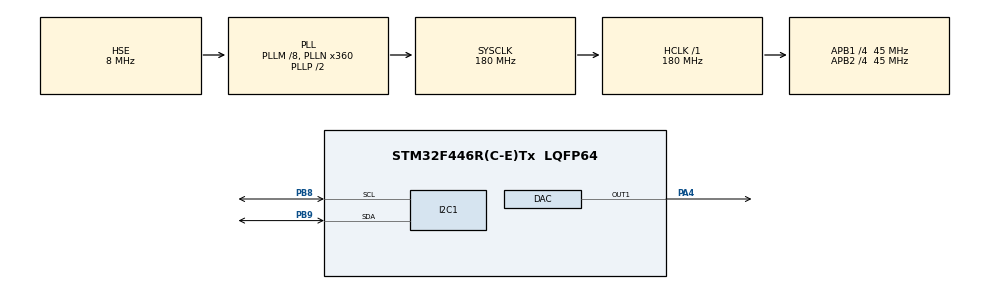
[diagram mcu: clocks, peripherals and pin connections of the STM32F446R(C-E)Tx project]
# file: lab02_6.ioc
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DAC.DAC_Trigger=DAC_TRIGGER_T6_TRGO
DAC.WaveGeneration=DISABLE
Dma.DAC1.0.Direction=DMA_MEMORY_TO_PERIPH
Dma.DAC1.0.FIFOMode=DMA_FIFOMODE_DISABLE
Dma.DAC1.0.Instance=DMA1_Stream5
Dma.DAC1.0.MemDataAlignment=DMA_MDATAALIGN_WORD
Dma.DAC1.0.MemInc=DMA_MINC_ENABLE
Dma.DAC1.0.Mode=DMA_CIRCULAR
Dma.DAC1.0.PeriphDataAlignment=DMA_PDATAALIGN_WORD
Dma.DAC1.0.PeriphInc=DMA_PINC_DISABLE
Dma.DAC1.0.Priority=DMA_PRIORITY_HIGH
Dma.Request0=DAC1
I2C1.I2C_Mode=I2C_Fast
Mcu.Family=STM32F4
Mcu.Name=STM32F446R(C-E)Tx
Mcu.Package=LQFP64
NVIC.DMA1_Stream5_IRQn=true\:0\:0\:false\:false\:true\:false\:true\:true
NVIC.PriorityGroup=NVIC_PRIORITYGROUP_4
PA13.Mode=Serial_Wire
PA13.Signal=SYS_JTMS-SWDIO
PA14.Mode=Serial_Wire
PA14.Signal=SYS_JTCK-SWCLK
PA4.Signal=COMP_DAC1_group
PB8.Mode=I2C
PB8.Signal=I2C1_SCL
PB9.Mode=I2C
PB9.Signal=I2C1_SDA
PH0-OSC_IN.Mode=HSE-External-Oscillator
PH0-OSC_IN.Signal=RCC_OSC_IN
PH1-OSC_OUT.Mode=HSE-External-Oscillator
PH1-OSC_OUT.Signal=RCC_OSC_OUT
ProjectManager.HeapSize=0x200
ProjectManager.StackSize=0x400
ProjectManager.TargetToolchain=STM32CubeIDE
RCC.AHBFreq_Value=180000000
RCC.APB1CLKDivider=RCC_HCLK_DIV4
RCC.APB1Freq_Value=45000000
RCC.APB1TimFreq_Value=90000000
RCC.APB2CLKDivider=RCC_HCLK_DIV4
RCC.APB2Freq_Value=45000000
RCC.APB2TimFreq_Value=90000000
RCC.CortexFreq_Value=180000000
RCC.HCLKFreq_Value=180000000
RCC.HSE_VALUE=8000000
RCC.PLLM=8
RCC.PLLN=360
RCC.PLLSourceVirtual=RCC_PLLSOURCE_HSE
RCC.SYSCLKFreq_VALUE=180000000
RCC.SYSCLKSource=RCC_SYSCLKSOURCE_PLLCLK
RCC.USBFreq_Value=180000000
RCC.VCOOutputFreq_Value=360000000
SH.COMP_DAC1_group.0=DAC_OUT1,DAC_OUT1
TIM6.AutoReloadPreload=TIM_AUTORELOAD_PRELOAD_ENABLE
TIM6.Period=90-1
TIM6.Prescaler=1-1
TIM6.TIM_MasterOutputTrigger=TIM_TRGO_UPDATE
VP_TIM6_VS_ClockSourceINT.Mode=Enable_Timer
board=custom

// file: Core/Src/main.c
/* USER CODE BEGIN Header */
/**
  ******************************************************************************
  * @file           : main.c
  * @brief          : Main program body
  ******************************************************************************
  * @attention
  *
  * Copyright (c) 2026 STMicroelectronics.
  * All rights reserved.
  *
  * This software is licensed under terms that can be found in the LICENSE file
  * in the root directory of this software component.
  * If no LICENSE file comes with this software, it is provided AS-IS.
  *
  ******************************************************************************
  */
/* USER CODE END Header */
#include "main.h"

/* USER CODE BEGIN Includes */
#include <math.h>
/* USER CODE END Includes */

/* USER CODE BEGIN PD */
#define PI 3.1415926536
/* USER CODE END PD */

DAC_HandleTypeDef hdac;
DMA_HandleTypeDef hdma_dac1;

I2C_HandleTypeDef hi2c1;

TIM_HandleTypeDef htim6;

/* USER CODE BEGIN PV */
uint32_t waveTable[1000];
/* USER CODE END PV */

void SystemClock_Config(void);
static void MX_GPIO_Init(void);
static void MX_DMA_Init(void);
static void MX_I2C1_Init(void);
static void MX_DAC_Init(void);
static void MX_TIM6_Init(void);

int main(void)
{

  /* USER CODE BEGIN 1 */
  int i;
  /* USER CODE END 1 */

  /* MCU Configuration--------------------------------------------------------*/

  /* Reset of all peripherals, Initializes the Flash interface and the Systick. */
  HAL_Init();

  /* Configure the system clock */
  SystemClock_Config();

  /* Initialize all configured peripherals */
  MX_GPIO_Init();
  MX_DMA_Init();
  MX_I2C1_Init();
  MX_DAC_Init();
  MX_TIM6_Init();
  /* USER CODE BEGIN 2 */
  // Generate sine wave
    for(i=0;i<1000;i++)
       waveTable[i] = (uint32_t)(sin((float)i*2*PI/1000.0)*(1241.212121)+2048);
    HAL_DAC_Start_DMA(&hdac,DAC_CHANNEL_1,waveTable,1000,DAC_ALIGN_12B_R);
    HAL_TIM_Base_Start(&htim6);

  /* USER CODE END 2 */

  /* Infinite loop */
  while (1)
  {

  }
}

void SystemClock_Config(void)
{
  RCC_OscInitTypeDef RCC_OscInitStruct = {0};
  RCC_ClkInitTypeDef RCC_ClkInitStruct = {0};

  /** Configure the main internal regulator output voltage
  */
  __HAL_RCC_PWR_CLK_ENABLE();
  __HAL_PWR_VOLTAGESCALING_CONFIG(PWR_REGULATOR_VOLTAGE_SCALE1);

  /** Initializes the RCC Oscillators according to the specified parameters
  * in the RCC_OscInitTypeDef structure.
  */
  RCC_OscInitStruct.OscillatorType = RCC_OSCILLATORTYPE_HSE;
  RCC_OscInitStruct.HSEState = RCC_HSE_ON;
  RCC_OscInitStruct.PLL.PLLState = RCC_PLL_ON;
  RCC_OscInitStruct.PLL.PLLSource = RCC_PLLSOURCE_HSE;
  RCC_OscInitStruct.PLL.PLLM = 8;
  RCC_OscInitStruct.PLL.PLLN = 360;
  RCC_OscInitStruct.PLL.PLLP = RCC_PLLP_DIV2;
  RCC_OscInitStruct.PLL.PLLQ = 2;
  RCC_OscInitStruct.PLL.PLLR = 2;
  if (HAL_RCC_OscConfig(&RCC_OscInitStruct) != HAL_OK)
  {
    Error_Handler();
  }

  /** Activate the Over-Drive mode
  */
  if (HAL_PWREx_EnableOverDrive() != HAL_OK)
  {
    Error_Handler();
  }

  /** Initializes the CPU, AHB and APB buses clocks
  */
  RCC_ClkInitStruct.ClockType = RCC_CLOCKTYPE_HCLK|RCC_CLOCKTYPE_SYSCLK
                              |RCC_CLOCKTYPE_PCLK1|RCC_CLOCKTYPE_PCLK2;
  RCC_ClkInitStruct.SYSCLKSource = RCC_SYSCLKSOURCE_PLLCLK;
  RCC_ClkInitStruct.AHBCLKDivider = RCC_SYSCLK_DIV1;
  RCC_ClkInitStruct.APB1CLKDivider = RCC_HCLK_DIV4;
  RCC_ClkInitStruct.APB2CLKDivider = RCC_HCLK_DIV4;

  if (HAL_RCC_ClockConfig(&RCC_ClkInitStruct, FLASH_LATENCY_5) != HAL_OK)
  {
    Error_Handler();
  }
}

static void MX_DAC_Init(void)
{

  DAC_ChannelConfTypeDef sConfig = {0};

  /** DAC Initialization
  */
  hdac.Instance = DAC;
  if (HAL_DAC_Init(&hdac) != HAL_OK)
  {
    Error_Handler();
  }

  /** DAC channel OUT1 config
  */
  sConfig.DAC_Trigger = DAC_TRIGGER_T6_TRGO;
  sConfig.DAC_OutputBuffer = DAC_OUTPUTBUFFER_ENABLE;
  if (HAL_DAC_ConfigChannel(&hdac, &sConfig, DAC_CHANNEL_1) != HAL_OK)
  {
    Error_Handler();
  }

}

static void MX_I2C1_Init(void)
{

  hi2c1.Instance = I2C1;
  hi2c1.Init.ClockSpeed = 400000;
  hi2c1.Init.DutyCycle = I2C_DUTYCYCLE_2;
  hi2c1.Init.OwnAddress1 = 0;
  hi2c1.Init.AddressingMode = I2C_ADDRESSINGMODE_7BIT;
  hi2c1.Init.DualAddressMode = I2C_DUALADDRESS_DISABLE;
  hi2c1.Init.OwnAddress2 = 0;
  hi2c1.Init.GeneralCallMode = I2C_GENERALCALL_DISABLE;
  hi2c1.Init.NoStretchMode = I2C_NOSTRETCH_DISABLE;
  if (HAL_I2C_Init(&hi2c1) != HAL_OK)
  {
    Error_Handler();
  }

}

static void MX_TIM6_Init(void)
{

  TIM_MasterConfigTypeDef sMasterConfig = {0};

  htim6.Instance = TIM6;
  htim6.Init.Prescaler = 1-1;
  htim6.Init.CounterMode = TIM_COUNTERMODE_UP;
  htim6.Init.Period = 90-1;
  htim6.Init.AutoReloadPreload = TIM_AUTORELOAD_PRELOAD_ENABLE;
  if (HAL_TIM_Base_Init(&htim6) != HAL_OK)
  {
    Error_Handler();
  }
  sMasterConfig.MasterOutputTrigger = TIM_TRGO_UPDATE;
  sMasterConfig.MasterSlaveMode = TIM_MASTERSLAVEMODE_DISABLE;
  if (HAL_TIMEx_MasterConfigSynchronization(&htim6, &sMasterConfig) != HAL_OK)
  {
    Error_Handler();
  }

}

static void MX_DMA_Init(void)
{

  /* DMA controller clock enable */
  __HAL_RCC_DMA1_CLK_ENABLE();

  /* DMA interrupt init */
  /* DMA1_Stream5_IRQn interrupt configuration */
  HAL_NVIC_SetPriority(DMA1_Stream5_IRQn, 0, 0);
  HAL_NVIC_EnableIRQ(DMA1_Stream5_IRQn);

}

static void MX_GPIO_Init(void)
{

  /* GPIO Ports Clock Enable */
  __HAL_RCC_GPIOH_CLK_ENABLE();
  __HAL_RCC_GPIOA_CLK_ENABLE();
  __HAL_RCC_GPIOB_CLK_ENABLE();

}

void Error_Handler(void)
{
  __disable_irq();
  while (1)
  {
  }
}
